AUTOSAR XML (schema 00048)
package /ComponentTypes
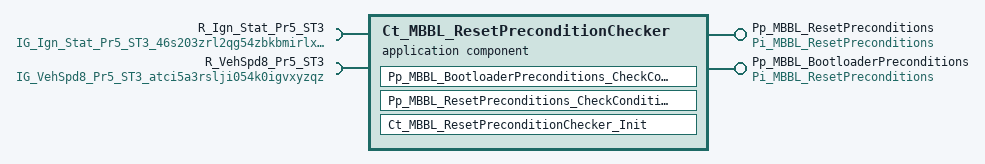
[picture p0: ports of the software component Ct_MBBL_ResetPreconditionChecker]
  application sw component type Ct_MBBL_ResetPreconditionChecker
    provide port Pp_MBBL_ResetPreconditions: server-com-spec{operation=CheckConditions, queue-length=1}, provided-interface=Pi_MBBL_ResetPreconditions
    provide port Pp_MBBL_BootloaderPreconditions: server-com-spec{operation=CheckConditions, queue-length=1}, provided-interface=Pi_MBBL_ResetPreconditions
    require port R_Ign_Stat_Pr5_ST3: nonqueued-receiver-com-spec{data-element=Ign_Stat_Pr5_ST3, filter=data-filter-type=ALWAYS, init-value=constant-reference=XDIS_9fnatjo7ibmc7ug14uhxholnb}, required-interface=IG_Ign_Stat_Pr5_ST3_46s203zrl2qg54zbkbmirlx2b  # Ignition state (degraded)
    require port R_VehSpd8_Pr5_ST3: nonqueued-receiver-com-spec{data-element=VehSpd8_Pr5_ST3, end-to-end-transformation-com-spec-props{disable-end-to-end-check=false, max-delta-counter=3, max-error-state-init=0, max-error-state-invalid=0, max-error-state-valid=0, min-ok-state-init=1, min-ok-state-invalid=1, min-ok-state-valid=1, window-size=10}, filter=data-filter-type=ALWAYS, init-value=constant-reference=XDIS_dj45cy8ua216iwtra2tj416zq}, required-interface=IG_VehSpd8_Pr5_ST3_atci5a3rslji054k0igvxyzqz  # vehicle Spd 8 ST3 (degraded)
    behavior Ct_MBBL_ResetPreconditionChecker_InternalBehavior: data-type-mapping=[DATA_TYPE_MAPPING_SET, DataTypeMappings_DEV]
      operation invoked event OIT_Pp_MBBL_BootloaderPreconditions_CheckConditions_Pp_MBBL_BootloaderPreconditions_CheckConditions: start-on-event=Pp_MBBL_BootloaderPreconditions_CheckConditions, operation=Pp_MBBL_BootloaderPreconditions.CheckConditions
      operation invoked event OIT_Pp_MBBL_ResetPreconditions_CheckConditions_Pp_MBBL_ResetPreconditions_CheckConditions: start-on-event=Pp_MBBL_ResetPreconditions_CheckConditions, operation=Pp_MBBL_ResetPreconditions.CheckConditions
      init event Ct_MBBL_ResetPreconditionChecker_InitEvent: start-on-event=Ct_MBBL_ResetPreconditionChecker_Init
      runnable Pp_MBBL_BootloaderPreconditions_CheckConditions
        data-receive-point-by-arguments:
          access REC_R_VehSpd8_Pr5_ST3_VehSpd8_Pr5_ST3: accessed-variable=R_VehSpd8_Pr5_ST3.VehSpd8_Pr5_ST3
      runnable Pp_MBBL_ResetPreconditions_CheckConditions
        data-receive-point-by-arguments:
          access REC_R_VehSpd8_Pr5_ST3_VehSpd8_Pr5_ST3: accessed-variable=R_VehSpd8_Pr5_ST3.VehSpd8_Pr5_ST3
      runnable Ct_MBBL_ResetPreconditionChecker_Init
  swc implementation Ct_MBBL_ResetPreconditionChecker_Implementation: behavior=Ct_MBBL_ResetPreconditionChecker_InternalBehavior
    code-descriptors:
      code Default: artifact-descriptors=autosar-engineering-object=category=SWSRC
